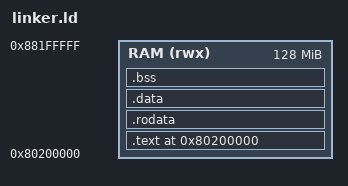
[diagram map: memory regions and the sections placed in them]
OUTPUT_ARCH(riscv)
ENTRY(_start)

MEMORY
{
    RAM (rwx) : ORIGIN = 0x80200000, LENGTH = 128M
}

SECTIONS
{
    . = ORIGIN(RAM);
    __kernel_start = .;

    .text : ALIGN(4K) {
        KEEP(*(.text.boot))
        *(.text .text.*)
    } > RAM

    .rodata : ALIGN(4K) {
        *(.rodata .rodata.*)
    } > RAM

    .data : ALIGN(4K) {
        *(.data .data.*)
    } > RAM

    .bss (NOLOAD) : ALIGN(4K) {
        __bss_start = .;
        *(.bss .bss.*)
        *(COMMON)
        . = ALIGN(16);
        __bss_end = .;
    } > RAM

    . = ALIGN(16);
    __stack_start = .;
    . += 64K;
    __stack_top = .;
    __kernel_end = .;

    /DISCARD/ : {
        *(.eh_frame .eh_frame.*)
        *(.comment .comment.*)
    }
}
